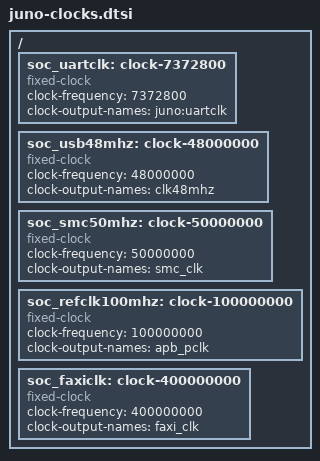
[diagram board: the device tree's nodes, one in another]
/*
 * ARM Juno Platform clocks
 *
 * Copyright (c) 2013-2014 ARM Ltd
 *
 * This file is licensed under a dual GPLv2 or BSD license.
 *
 */
/ {
	/* SoC fixed clocks */
	soc_uartclk: clock-7372800 {
		compatible = "fixed-clock";
		#clock-cells = <0>;
		clock-frequency = <7372800>;
		clock-output-names = "juno:uartclk";
	};

	soc_usb48mhz: clock-48000000 {
		compatible = "fixed-clock";
		#clock-cells = <0>;
		clock-frequency = <48000000>;
		clock-output-names = "clk48mhz";
	};

	soc_smc50mhz: clock-50000000 {
		compatible = "fixed-clock";
		#clock-cells = <0>;
		clock-frequency = <50000000>;
		clock-output-names = "smc_clk";
	};

	soc_refclk100mhz: clock-100000000 {
		compatible = "fixed-clock";
		#clock-cells = <0>;
		clock-frequency = <100000000>;
		clock-output-names = "apb_pclk";
	};

	soc_faxiclk: clock-400000000 {
		compatible = "fixed-clock";
		#clock-cells = <0>;
		clock-frequency = <400000000>;
		clock-output-names = "faxi_clk";
	};
};
